# LCDC register map
Registers from a debugger description file.
Registers are 32-bit, access not given, no defined reset value unless marked. A register's access mark holds for its fields unless they carry their own. Addresses are absolute; registers are grouped by the start of their names; lines under a group give offsets from that group; [hi:lo] are bit positions; {n}, {i} and the like mark numbered series; 'fields as' and 'values as' point back to an identical list; <NAME> marks a mode.

## rLcd
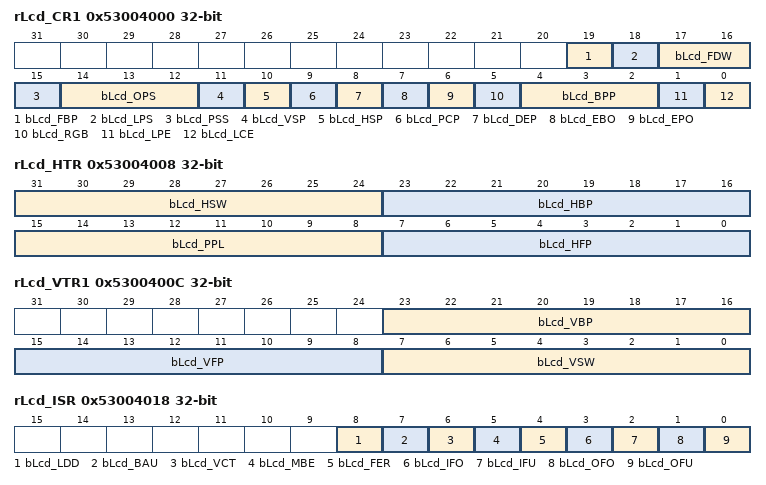
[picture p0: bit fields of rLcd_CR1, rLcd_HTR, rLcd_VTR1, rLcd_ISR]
0x53004000 rLcd_CR1
  [19] bLcd_FBP, [18] bLcd_LPS, [17:16] bLcd_FDW, [15] bLcd_PSS, [14:12] bLcd_OPS, [11] bLcd_VSP, [10] bLcd_HSP, [9] bLcd_PCP, [8] bLcd_DEP, [7] bLcd_EBO, [6] bLcd_EPO, [5] bLcd_RGB, [4:2] bLcd_BPP, [1] bLcd_LPE, [0] bLcd_LCE
0x53004008 rLcd_HTR
  [31:24] bLcd_HSW, [23:16] bLcd_HBP, [15:8] bLcd_PPL, [7:0] bLcd_HFP
0x5300400C rLcd_VTR1
  [23:16] bLcd_VBP, [15:8] bLcd_VFP, [7:0] bLcd_VSW
0x53004010 rLcd_VTR2
  [11:0] bLcd_LPP
0x53004014 rLcd_PCTR
  [10] bLcd_PCR
0x53004018 rLcd_ISR
  [8] bLcd_LDD, [7] bLcd_BAU, [6] bLcd_VCT, [5] bLcd_MBE, [4] bLcd_FER, [3] bLcd_IFO, [2] bLcd_IFU, [1] bLcd_OFO, [0] bLcd_OFU
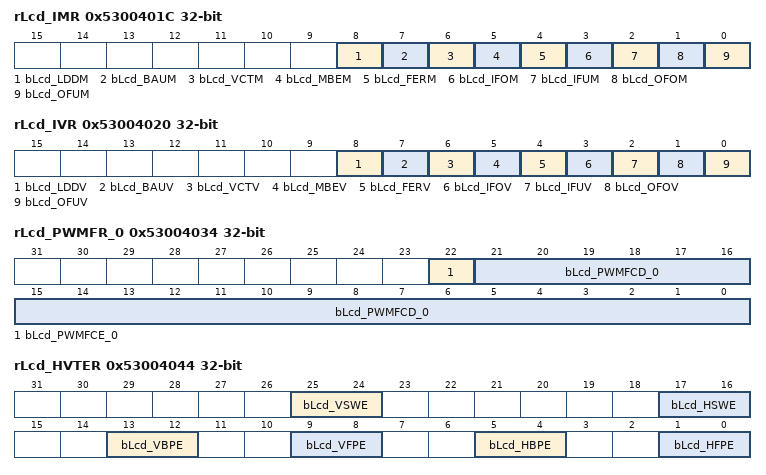
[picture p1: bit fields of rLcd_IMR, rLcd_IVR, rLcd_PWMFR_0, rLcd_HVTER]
0x5300401C rLcd_IMR
  [8] bLcd_LDDM, [7] bLcd_BAUM, [6] bLcd_VCTM, [5] bLcd_MBEM, [4] bLcd_FERM, [3] bLcd_IFOM, [2] bLcd_IFUM, [1] bLcd_OFOM, [0] bLcd_OFUM
0x53004020 rLcd_IVR ro
  [8] bLcd_LDDV, [7] bLcd_BAUV, [6] bLcd_VCTV, [5] bLcd_MBEV, [4] bLcd_FERV, [3] bLcd_IFOV, [2] bLcd_IFUV, [1] bLcd_OFOV, [0] bLcd_OFUV
0x53004024 rLcd_ISCR
  [2:0] bLcd_VSC
0x53004028 rLcd_DBAR
  [31:3] bLcd_DBAR
0x5300402C rLcd_DCAR ro
  [31:0] bLcd_DCAR
0x53004030 rLcd_DEAR
  [31:0] bLcd_DEAR
0x53004034 rLcd_PWMFR_0
  [22] bLcd_PWMFCE_0, [21:0] bLcd_PWMFCD_0
0x53004038 rLcd_PWMDCR_0
  [7:0] bLcd_PWMDC_0
0x53004044 rLcd_HVTER
  [25:24] bLcd_VSWE, [17:16] bLcd_HSWE, [13:12] bLcd_VBPE, [9:8] bLcd_VFPE, [5:4] bLcd_HBPE, [1:0] bLcd_HFPE
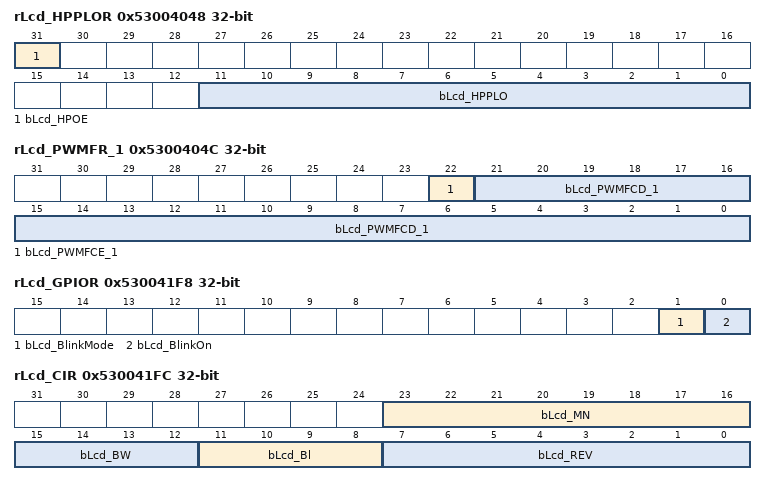
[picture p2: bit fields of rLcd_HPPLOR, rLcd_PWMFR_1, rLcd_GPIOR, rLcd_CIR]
0x53004048 rLcd_HPPLOR
  [31] bLcd_HPOE, [11:0] bLcd_HPPLO
0x5300404C rLcd_PWMFR_1
  [22] bLcd_PWMFCE_1, [21:0] bLcd_PWMFCD_1
0x53004050 rLcd_PWMDCR_1
  [7:0] bLcd_PWMDC_1
0x530041F8 rLcd_GPIOR
  [1] bLcd_BlinkMode, [0] bLcd_BlinkOn
0x530041FC rLcd_CIR ro
  [23:16] bLcd_MN, [15:12] bLcd_BW, [11:8] bLcd_Bl, [7:0] bLcd_REV
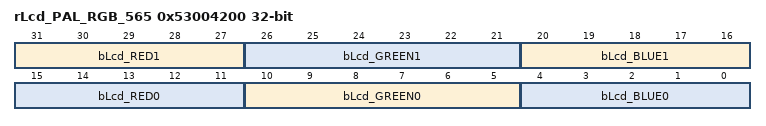
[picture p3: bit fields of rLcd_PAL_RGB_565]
0x53004200 rLcd_PAL_RGB_565
  [31:27] bLcd_RED1, [26:21] bLcd_GREEN1, [20:16] bLcd_BLUE1, [15:11] bLcd_RED0, [10:5] bLcd_GREEN0, [4:0] bLcd_BLUE0
